AUTOSAR XML (schema 4-0-3)
standard types defined: UInt32, UInt8
package /AUTOSAR_Platform/DataConstrs
  range DC_UInt8: raw 0..255
package /PATAC/MSM/ComponentTypes
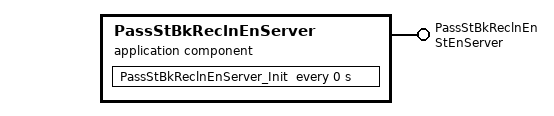
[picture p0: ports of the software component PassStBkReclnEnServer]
  application sw component type PassStBkReclnEnServer
    provide port PassStBkReclnEn: provided-com-specs=[{operation=Clear, queue-length=1}, {operation=Get, queue-length=1}, {operation=Set, queue-length=1}], provided-interface=StEnServer
    behavior PassStBkReclnEnServer_InternalBehavior
      operation invoked event OIT_PassStBkReclnEn_Clear_PassStBkReclnEn_Clear: start-on-event=PassStBkReclnEn_Clear, operation=PassStBkReclnEn.Clear
      operation invoked event OIT_PassStBkReclnEn_Get_PassStBkReclnEn_Get: start-on-event=PassStBkReclnEn_Get, operation=PassStBkReclnEn.Get
      operation invoked event OIT_PassStBkReclnEn_Set_PassStBkReclnEn_Set: start-on-event=PassStBkReclnEn_Set, operation=PassStBkReclnEn.Set
      timing event PassStBkReclnEnServer_InitEvent: start-on-event=PassStBkReclnEnServer_Init, period=0
      4 x runnable:
        PassStBkReclnEn_Clear
        PassStBkReclnEn_Get
        PassStBkReclnEn_Set
        PassStBkReclnEnServer_Init
  swc implementation PassStBkReclnEnServer_Implementation: behavior=PassStBkReclnEnServer_InternalBehavior
    code-descriptors:
      code Default: artifact-descriptors=autosar-engineering-object={short-label=Default, category=SWSRC}
package /PATAC/MSM/ModeAdjust/PortInterface
  client server interface StEnServer
    operation Clear
      arg data: type=UInt8, direction=IN, server-argument-impl-policy=USE-ARGUMENT-TYPE
    operation Get
      arg data: type=UInt32, direction=OUT, server-argument-impl-policy=USE-ARGUMENT-TYPE
    operation Set
      arg data: type=UInt8, direction=IN, server-argument-impl-policy=USE-ARGUMENT-TYPE
